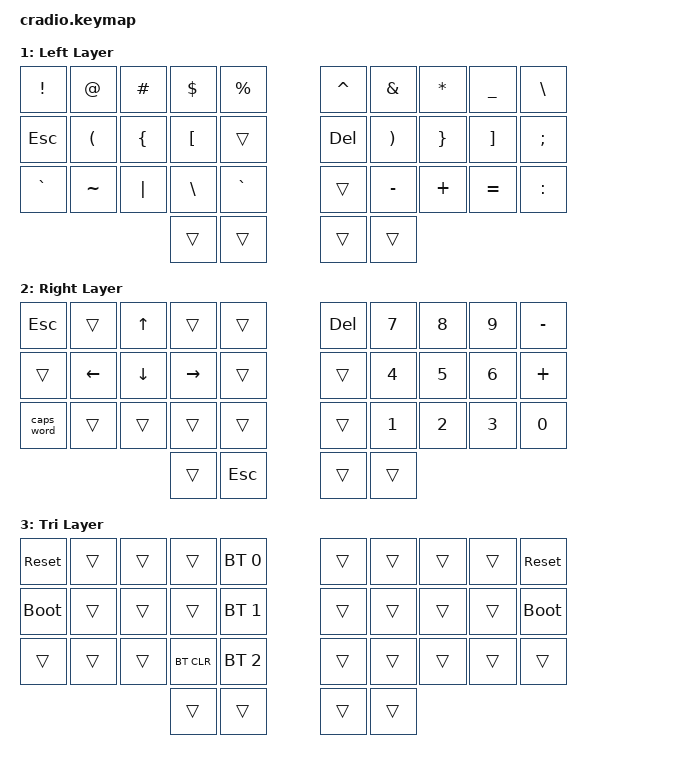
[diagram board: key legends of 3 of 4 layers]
// Copyright (c) 2022 The ZMK Contributors
// SPDX-License-Identifier: MIT

#include <behaviors.dtsi>
#include <dt-bindings/zmk/keys.h>
#include <dt-bindings/zmk/bt.h>

// Home row mods macro
// Home Row Mod Left
#define HRML(k1,k2,k3,k4) &ht LSHIFT k1  &ht LCTRL k2  &ht LALT k3  &ht LGUI k4
// Home Row Left Thumb
#define HRMTL(k1) &ht LGUI k1
// Home Row Mod Right
#define HRMR(k1,k2,k3,k4) &ht RGUI k1  &ht RCTRL k2  &ht RALT k3  &ht RSHIFT k4

/ {
    behaviors {
        ht: hold_tap {
            compatible = "zmk,behavior-hold-tap";
            #binding-cells = <2>;
            flavor = "tap-preferred";
            tapping-term-ms = <220>;
            quick-tap-ms = <150>;
            require-prior-idle-ms = <100>;
            bindings = <&kp>, <&kp>;
        };
    };

    conditional_layers {
        compatible = "zmk,conditional-layers";
        tri_layer {
            if-layers = <1 2>;
            then-layer = <3>;
        };
    };

    keymap {
        compatible = "zmk,keymap";
        default_layer {
            display-name = "Default Layer";
            bindings = <
        //╭──────────┬──────────┬──────────┬──────────┬──────────╮   ╭──────────┬──────────┬──────────┬──────────┬──────────╮
        //│  Q       │  W       │  E       │  R       │  T       │   │  Y       │  U       │  I       │  O       │  P       │
            &kp Q      &kp W      &kp E      &kp R      &kp T          &kp Y      &kp U      &kp I      &kp O      &kp P
        //├──────────┼──────────┼──────────┼──────────┼──────────┤   ├──────────┼──────────┼──────────┼──────────┼──────────┤
        //│  A       │  S       │  D       │  F       │  G       │   │  H       │  J       │  K       │  L       │ ' "      │
            HRML(A,        S,         D,         F)     &kp G          &kp H      HRMR(J,        K,         L,        SQT)
        //├──────────┼──────────┼──────────┼──────────┼──────────┤   ├──────────┼──────────┼──────────┼──────────┼──────────┤
        //│  Z       │  X       │  C       │  V       │  B       │   │  N       │  M       │ , <      │ . >      │ / ?      │
            &kp Z      &kp X      &kp C      &kp V      &kp B          &kp N      &kp M      &kp COMMA  &kp DOT    &kp FSLH
        //╰──────────┴──────────┴──────────┼──────────┼──────────┤   ├──────────┼──────────┼──────────┴──────────┴──────────╯
                                            &lt 1 TAB   HRMTL(ENTER)   &kp BSPC   &lt 2 SPACE
        //                                 ╰──────────┴──────────╯   ╰──────────┴──────────╯
            >;
        };

        left_layer {
            display-name = "Left Layer";
            bindings = <
        //╭──────────┬──────────┬──────────┬──────────┬──────────╮   ╭──────────┬──────────┬──────────┬──────────┬──────────╮
        //│  !       │  @       │  #       │  $       │  %       │   │  ^       │  &       │  *       │  _       │  \       │
            &kp EXCL   &kp AT     &kp HASH   &kp DLLR   &kp PRCNT     &kp CARET   &kp AMPS   &kp ASTRK   &kp UNDER  &kp BSLH         
        //├──────────┼──────────┼──────────┼──────────┼──────────┤   ├──────────┼──────────┼──────────┼──────────┼──────────┤
        //│          │  (       │  {       │  [       │          │   │  DEL     │  )       │  }       │  ]       │  ;       │        
             &kp ESC    &kp LPAR   &kp LBRC   &kp LBKT  &trans          &kp DEL    &kp RPAR   &kp RBRC   &kp RBKT  &kp SEMI                                               
        //├──────────┼──────────┼──────────┼──────────┼──────────┤   ├──────────┼──────────┼──────────┼──────────┼──────────┤
        //│    `     |      ~   │     |    │    /     │          │   │          │  _       │  +       │  =       │  :       │
            &kp GRAVE   &kp TILDE  &kp PIPE  &kp BSLH   &kp GRAVE      &trans     &kp MINUS   &kp PLUS   &kp EQUAL  &kp COLON
        //╰──────────┴──────────┴──────────┼──────────┼──────────┤   ├──────────┼──────────┼──────────┴──────────┴──────────╯
                                             &trans     &trans         &trans     &trans
        //                                 ╰──────────┴──────────╯   ╰──────────┴──────────╯
            >;
        };


        right_layer {
            display-name = "Right Layer";
            bindings = <
        //╭──────────┬──────────┬──────────┬──────────┬──────────╮   ╭──────────┬──────────┬──────────┬──────────┬──────────╮
        //│ ESC      │          │  UP      │          │          │   │ DEL      │ 7        │ 8        │ 9        │  -       │
            &kp ESC     &trans     &kp UP        &trans     &trans        &kp DEL    &kp N7     &kp N8     &kp N9      &kp MINUS
        //├──────────┼──────────┼──────────┼──────────┼──────────┤   ├──────────┼──────────┼──────────┼──────────┼──────────┤
        //│          │  LEFT    │  DOWN    │  RIGHT   │          │   │          │ 4        │ 5        │ 6        │  +       │
            &trans      &kp LEFT   &kp DOWN   &kp RIGHT &trans         &trans     &kp N4     &kp N5     &kp N6      &kp PLUS
        //├──────────┼──────────┼──────────┼──────────┼──────────┤   ├──────────┼──────────┼──────────┼──────────┼──────────┤
        //│ CAPS     │          │          │          │          │   │          │ 1        │ 2        │ 3        │  0       │
           &caps_word  &trans     &trans      &trans    &trans         &trans     &kp N1      &kp N2     &kp N3     &kp N0
        //╰──────────┴──────────┴──────────┼──────────┼──────────┤   ├──────────┼──────────┼──────────┴──────────┴──────────╯
                                              &trans     &kp ESC       &trans     &trans
        //                                 ╰──────────┴──────────╯   ╰──────────┴──────────╯
            >;
        };



        tri_layer {
            display-name = "Tri Layer";
            bindings = <
        //╭──────────┬──────────┬──────────┬──────────┬──────────╮   ╭──────────┬──────────┬──────────┬──────────┬──────────╮
        //│ RESET    │          │          │          │PROFILE 0 │   │          │          │          │          │  RESET   │
           &sys_reset  &trans     &trans     &trans    &bt BT_SEL 0    &trans     &trans     &trans     &trans    &sys_reset
        //├──────────┼──────────┼──────────┼──────────┼──────────┤   ├──────────┼──────────┼──────────┼──────────┼──────────┤
        //│BOOTLOADER│          │          │          │PROFILE 1 │   │          │          │          │          │BOOTLOADER│
          &bootloader  &trans     &trans     &trans    &bt BT_SEL 1    &trans     &trans     &trans     &trans    &bootloader
        //├──────────┼──────────┼──────────┼──────────┼──────────┤   ├──────────┼──────────┼──────────┼──────────┼──────────┤
        //│          │          │          │ CLEAR BT │PROFILE 2 │   │          │          │          │          │          │
            &trans     &trans     &trans    &bt BT_CLR &bt BT_SEL 2    &trans     &trans     &trans     &trans     &trans
        //╰──────────┴──────────┴──────────┼──────────┼──────────┤   ├──────────┼──────────┼──────────┴──────────┴──────────╯
                                             &trans     &trans         &trans     &trans
        //                                 ╰──────────┴──────────╯   ╰──────────┴──────────╯
            >;
        };
    };
};
